# STM32F302xC register map
File version: 1.0
Registers are 32-bit, read-write, reset 0x0 unless marked. A register's access mark holds for its fields unless they carry their own. Offsets are from the block's base; [hi:lo] are bit positions; {n}, {i} and the like mark numbered series.

## SYSCFG — System configuration controller
Base 0x40010000
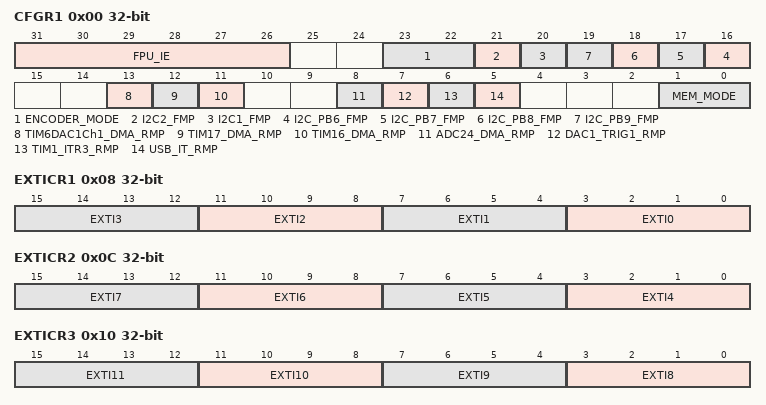
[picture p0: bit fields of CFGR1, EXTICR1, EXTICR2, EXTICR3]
0x00 CFGR1 — SYSCFG configuration register 1
  [31:26] FPU_IE — Floating Point Unit Interrupt Enable
  [23:22] ENCODER_MODE
  [21] I2C2_FMP — I2C2 Fast mode plus
  [20] I2C1_FMP — I2C1 Fast mode plus
  [n+10] I2C_PB{n}_FMP (n=6..9) — I2C PB{n} Fast mode plus
  [13] TIM6DAC1Ch1_DMA_RMP — Timer 6 / DAC1 Ch1 DMA remap
  [12] TIM17_DMA_RMP — Timer 17 DMA remap
  [11] TIM16_DMA_RMP — Timer 16 DMA remap
  [8] ADC24_DMA_RMP — ADC2 and ADC4 DMA remap
  [7] DAC1_TRIG1_RMP — DAC1 Trigger1 remap
  [6] TIM1_ITR3_RMP — Timer 1 ITR3 selection
  [5] USB_IT_RMP — USB interrupt remap
  [1:0] MEM_MODE — SYSCFG_Memory Remap Config
    0=FLASH; 1=SYSTEMFLASH; 3=SRAM
0x08 EXTICR1 — SYSCFG external interrupt configuration registers
  [4n+3:4n] EXTI{n} (n=0..3) — EXTI {n} configuration
0x0C EXTICR2 — SYSCFG external interrupt configuration registers
  [4n-13:4n-16] EXTI{n} (n=4..7) — EXTI {n} configuration
0x10 EXTICR3 — SYSCFG external interrupt configuration registers
  [4n-29:4n-32] EXTI{n} (n=8..11) — EXTI {n} configuration
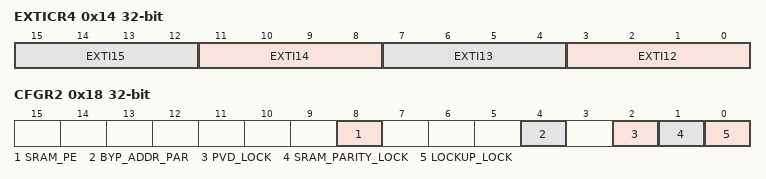
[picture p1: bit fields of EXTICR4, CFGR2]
0x14 EXTICR4 — SYSCFG external interrupt configuration registers
  [4n-45:4n-48] EXTI{n} (n=12..15) — EXTI {n} configuration
0x18 CFGR2 — SYSCFG configuration register 2
  [8] SRAM_PE — SRAM Parity error flag
  [4] BYP_ADDR_PAR — Disables the address parity check on RAM
  [2] PVD_LOCK — Enables and locks the PVD connection with TIMx Break Input, as well as the PVDE and PLS[2:0] in the PWR_CR register
  [1] SRAM_PARITY_LOCK — Enables and locks the SRAM_PARITY error signal with Break Input of TIMx
  [0] LOCKUP_LOCK — Enables and locks the LOCKUP (Hardfault) output of CortexM4 with Break Input of TIMx

## COMP1 — Analog Comparators
Base 0x4001001C; alternate view of COMP
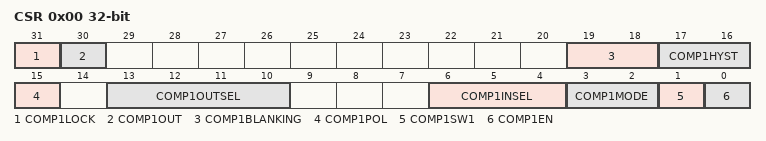
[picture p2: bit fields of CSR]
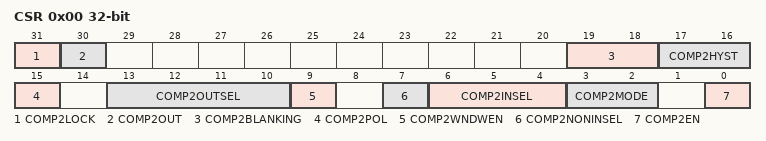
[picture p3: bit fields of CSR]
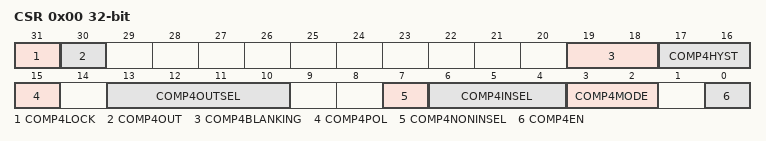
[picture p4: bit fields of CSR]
0x00 CSR — COMP control and status register
  [31] COMP1LOCK
  [30] COMP1OUT — COMP1 output level
  [19:18] COMP1BLANKING
  [17:16] COMP1HYST — COMP1 hysteresis
  [15] COMP1POL — COMP1 output polarity
  [13:10] COMP1OUTSEL — COMP1 output select
  [6:4] COMP1INSEL — COMP1 inverting input select
  [3:2] COMP1MODE — COMP1 power mode
  [1] COMP1SW1 — COMP1 SW1 switch control
  [0] COMP1EN — COMP1 enable

## COMP2 — Analog Comparators
Base 0x40010020; alternate view of COMP12_COMMON
0x00 CSR — COMP control and status register
  [31] COMP2LOCK
  [30] COMP2OUT — COMP2 output level
  [19:18] COMP2BLANKING
  [17:16] COMP2HYST — COMP2 hysteresis
  [15] COMP2POL — COMP2 output polarity
  [13:10] COMP2OUTSEL — COMP2 output select
  [9] COMP2WNDWEN — COMP2 window mode enable
  [7] COMP2NONINSEL — COMP2 non inverting input select
  [6:4] COMP2INSEL — COMP2 inverting input select
  [3:2] COMP2MODE — COMP2 power mode
  [0] COMP2EN — COMP2 enable

## COMP4 — Analog Comparators
Base 0x40010028
0x00 CSR — COMP control and status register
  [31] COMP4LOCK
  [30] COMP4OUT — COMP4 output level
  [19:18] COMP4BLANKING
  [17:16] COMP4HYST — COMP4 hysteresis
  [15] COMP4POL — COMP4 output polarity
  [13:10] COMP4OUTSEL — COMP4 output select
  [7] COMP4NONINSEL — COMP4 non inverting input select
  [6:4] COMP4INSEL — COMP4 inverting input select
  [3:2] COMP4MODE — COMP4 power mode
  [0] COMP4EN — COMP4 enable

## COMP6 — Analog Comparators
Base 0x40010030
Registers as COMP4 (with COMP4 read as COMP6).

## OPAMP1 — Operational Amplifier (OPAMP)
Base 0x40010038; alternate view of OPAMP
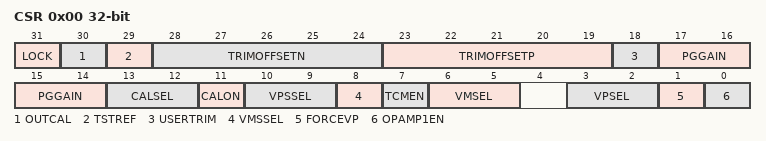
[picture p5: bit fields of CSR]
0x00 CSR — OPAMP control and status register
  [31] LOCK — OPAMP lock
  [30] OUTCAL — OPAMP output status flag
  [29] TSTREF — It enables the switch to put out the internal reference
  [28:24] TRIMOFFSETN — Offset trimming value (NMOS)
  [23:19] TRIMOFFSETP — Offset trimming value (PMOS)
  [18] USERTRIM — User trimming enable
  [17:14] PGGAIN — Gain in PGA mode
  [13:12] CALSEL — Calibration selection
  [11] CALON — Calibration mode enable
  [10:9] VPSSEL — Non inverting input secondary selection
  [8] VMSSEL — Inverting input secondary selection
  [7] TCMEN — Timer-Controlled Mux mode enable
  [6:5] VMSEL — Inverting input selection
  [3:2] VPSEL — Non inverting input selection
  [1] FORCEVP — Connect the internal references to the plus input of the OPAMPX
  [0] OPAMP1EN — OPAMP1 enable

## OPAMP2 — Operational Amplifier (OPAMP)
Base 0x4001003C
Registers as OPAMP1 (with OPAMP1 read as OPAMP2).
